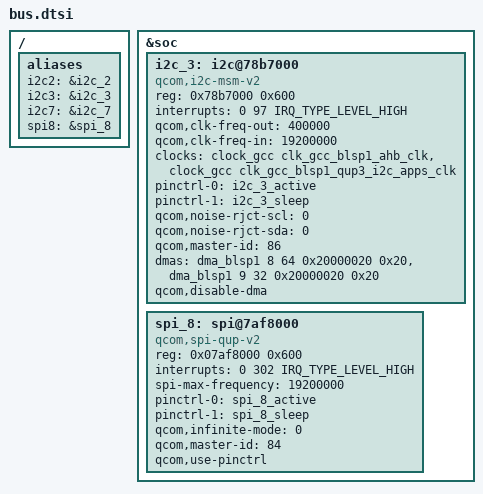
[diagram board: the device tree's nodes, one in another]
/ {
	aliases {
		i2c2 = &i2c_2;
		i2c3 = &i2c_3;
		/delete-property/ i2c6;
		i2c7 = &i2c_7;
		spi8 = &spi_8;
		/delete-property/ spi3;
	};
};

&soc {
	/delete-node/ i2c@7af5000;
	/delete-node/ spi@78b7000;

	i2c_3: i2c@78b7000 { /* BLSP1 QUP3 */
		status = "okay";
		compatible = "qcom,i2c-msm-v2";
		#address-cells = <1>;
		#size-cells = <0>;
		reg-names = "qup_phys_addr";
		reg = <0x78b7000 0x600>;
		interrupt-names = "qup_irq";
		interrupts = <0 97 IRQ_TYPE_LEVEL_HIGH>;
		qcom,clk-freq-out = <400000>;
		qcom,clk-freq-in  = <19200000>;
		clock-names = "iface_clk", "core_clk";
		clocks = <&clock_gcc clk_gcc_blsp1_ahb_clk>,
			<&clock_gcc clk_gcc_blsp1_qup3_i2c_apps_clk>;

		pinctrl-names = "i2c_active", "i2c_sleep";
		pinctrl-0 = <&i2c_3_active>;
		pinctrl-1 = <&i2c_3_sleep>;
		qcom,noise-rjct-scl = <0>;
		qcom,noise-rjct-sda = <0>;
		qcom,master-id = <86>;
		dmas = <&dma_blsp1 8 64 0x20000020 0x20>,
			<&dma_blsp1 9 32 0x20000020 0x20>;
		dma-names = "tx", "rx";
		qcom,disable-dma;
	};

	spi_8: spi@7af8000 { /* BLSP2 QUP3 */
		compatible = "qcom,spi-qup-v2";
		status = "ok";
		#address-cells = <1>;
		#size-cells = <0>;
		reg-names = "spi_physical";
		reg = <0x07af8000 0x600>;
		interrupt-names = "spi_irq";
		interrupts = <0 302 IRQ_TYPE_LEVEL_HIGH>;
		spi-max-frequency = <19200000>;

		pinctrl-names = "spi_default", "spi_sleep";
		pinctrl-0 = <&spi_8_active>;
		pinctrl-1 = <&spi_8_sleep>;
		qcom,infinite-mode = <0>;
		qcom,master-id = <84>;
		qcom,use-pinctrl;
	};
};
